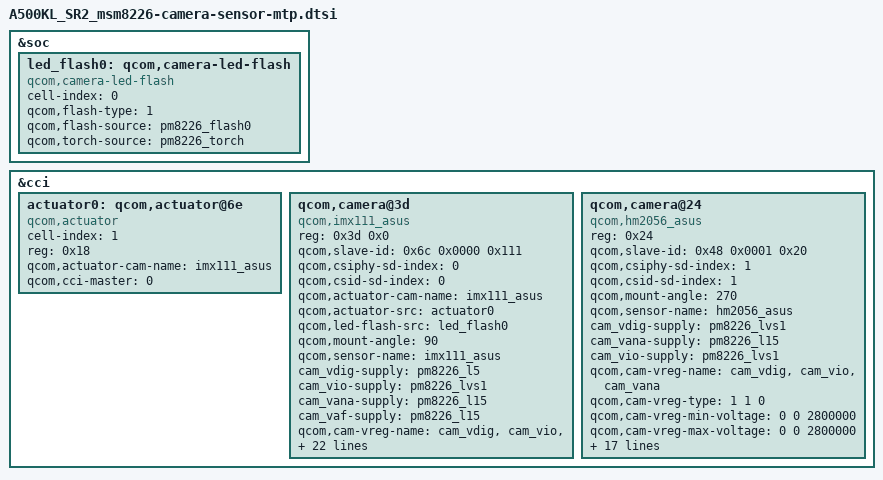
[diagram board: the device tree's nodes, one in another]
/*
 * Copyright (c) 2013, The Linux Foundation. All rights reserved.
 *
 * This program is free software; you can redistribute it and/or modify
 * it under the terms of the GNU General Public License version 2 and
 * only version 2 as published by the Free Software Foundation.
 *
 * This program is distributed in the hope that it will be useful,
 * but WITHOUT ANY WARRANTY; without even the implied warranty of
 * MERCHANTABILITY or FITNESS FOR A PARTICULAR PURPOSE.  See the
 * GNU General Public License for more details.
 */

&soc {

	led_flash0: qcom,camera-led-flash {
		cell-index = <0>;
		compatible = "qcom,camera-led-flash";
		qcom,flash-type = <1>;
		qcom,flash-source = <&pm8226_flash0>;
		qcom,torch-source = <&pm8226_torch>;
	};
};

&cci {

	actuator0: qcom,actuator@6e {
		cell-index = <1>;
		reg = <0x18>;
		compatible = "qcom,actuator";
		qcom,actuator-cam-name="imx111_asus";
		qcom,cci-master = <0>;
	};

	qcom,camera@3d {
		compatible = "qcom,imx111_asus";
		reg = <0x3d 0x0>;
		qcom,slave-id = <0x6c 0x0000 0x111>;
		qcom,csiphy-sd-index = <0>;
		qcom,csid-sd-index = <0>;
		qcom,actuator-cam-name="imx111_asus";
		qcom,actuator-src = <&actuator0>;
		qcom,led-flash-src = <&led_flash0>;
		qcom,mount-angle = <90>;
		qcom,sensor-name = "imx111_asus";
		cam_vdig-supply = <&pm8226_l5>;//1.0v
		cam_vio-supply = <&pm8226_lvs1>;//1.8v
		cam_vana-supply = <&pm8226_l15>;// module2.8v
		cam_vaf-supply = <&pm8226_l15>;//2.8v
		qcom,cam-vreg-name = "cam_vdig", "cam_vio", "cam_vana","cam_vaf";
		qcom,cam-vreg-type = <0 1 0 0>;
		qcom,cam-vreg-min-voltage = <1200000  1800000 2800000 2800000>;
		qcom,cam-vreg-max-voltage = <1200000 1800000  2800000 2800000>;
		qcom,cam-vreg-op-mode = <1200000 1800000  2800000 2800000>;
		qcom,gpio-no-mux = <0>;
		gpios = <&msmgpio 26 0>,
				<&msmgpio 38 0>,
				<&msmgpio 24 0>,
				<&msmgpio 23 0>;
		qcom,gpio-cam_pwdn =<1>;
		qcom,gpio-cam_1p8_en = <2>;
		qcom,gpio-cam_2p8_en = <3>;
		qcom,gpio-req-tbl-num = <0>;
		qcom,gpio-req-tbl-flags = <1>;
		qcom,gpio-req-tbl-label = "CAMIF_MCLK";
		qcom,csi-lane-assign = <0x4320>;
		qcom,csi-lane-mask = <0x7>;
		qcom,sensor-position = <0>;
		qcom,sensor-mode = <1>;
		qcom,cci-master = <0>;
		status = "ok";
	};

	qcom,camera@24 {
		compatible = "qcom,hm2056_asus";
		reg = <0x24>;
		qcom,slave-id = <0x48 0x0001 0x20>;
		qcom,csiphy-sd-index = <1>;
		qcom,csid-sd-index = <1>;
		qcom,mount-angle = <270>;
		qcom,sensor-name = "hm2056_asus";
		cam_vdig-supply = <&pm8226_lvs1>;
		cam_vana-supply = <&pm8226_l15>;
		cam_vio-supply = <&pm8226_lvs1>;
		qcom,cam-vreg-name ="cam_vdig", "cam_vio", "cam_vana";
		qcom,cam-vreg-type = <1 1 0>;
		qcom,cam-vreg-min-voltage = <0 0 2800000>;
		qcom,cam-vreg-max-voltage = <0 0 2800000>;
		qcom,cam-vreg-op-mode = <0 0 2800000>;
		qcom,gpio-no-mux = <0>;
		gpios = <&msmgpio 26 0>,
				<&msmgpio 2 0>,
				<&msmgpio 1 0>,
				<&msmgpio 24 0>,
				<&msmgpio 23 0>,
				<&msmgpio 3 0>;
		qcom,gpio-cam_reset = <1>;
		qcom,gpio-cam_pwdn = <2>;
		qcom,gpio-cam_1p8_en = <3>;
		qcom,gpio-cam_2p8_en = <4>;
		qcom,gpio-cam_camid = <5>;
		qcom,gpio-req-tbl-num = <0>;
		qcom,gpio-req-tbl-flags = <1>;
		qcom,gpio-req-tbl-label = "CAMIF_MCLK";
		qcom,csi-lane-assign = <0x4320>;
		qcom,csi-lane-mask = <0x3>;
		qcom,sensor-position = <1>;
		qcom,sensor-mode = <1>;
		qcom,cci-master = <0>;
		status = "ok";
	};
};
